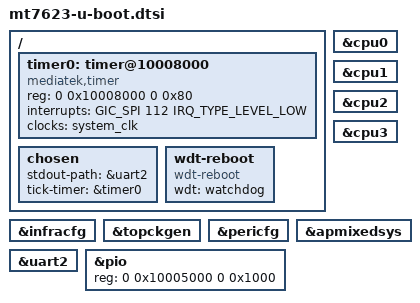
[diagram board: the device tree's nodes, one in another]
// SPDX-License-Identifier: GPL-2.0
/*
 * Copyright (c) 2019 MediaTek Inc.
 * Author: Sam Shih <sam.shih@mediatek.com>
 */

/ {
	timer0: timer@10008000 {
		compatible = "mediatek,timer";
		reg = <0 0x10008000 0 0x80>;
		interrupts = <GIC_SPI 112 IRQ_TYPE_LEVEL_LOW>;
		clocks = <&system_clk>;
		clock-names = "system-clk";
		bootph-all;
	};

	chosen {
		stdout-path = &uart2;
		tick-timer = &timer0;
	};

	wdt-reboot {
		compatible = "wdt-reboot";
		wdt = <&watchdog>;
	};
};

/delete-node/ &bls;
/delete-node/ &larb0;
/delete-node/ &larb1;
/delete-node/ &larb2;
/delete-node/ &iommu;
/delete-node/ &jpegdec;
/delete-node/ &smi_common;
/delete-node/ &ovl;
/delete-node/ &rdma0;
/delete-node/ &rdma1;
/delete-node/ &color;
/delete-node/ &mutex;
/delete-node/ &btif;
/delete-node/ &cec;
/delete-node/ &cir;
/delete-node/ &crypto;
/delete-node/ &dpi0;
/delete-node/ &dsi;
/delete-node/ &mipi_tx0;
/delete-node/ &gmac0;
/delete-node/ &gmac1;
/delete-node/ &eth;
/delete-node/ &hdmi0;
/delete-node/ &hdmiddc0;
/delete-node/ &hdmi_phy;
/delete-node/ &i2c0;
/delete-node/ &i2c1;
/delete-node/ &i2c2;
/delete-node/ &mali;
/delete-node/ &mmc0;
/delete-node/ &mmc1;
/delete-node/ &mt6323keys;
/delete-node/ &mt6323_leds;
/delete-node/ &pcie;
/delete-node/ &pcie0_phy;
/delete-node/ &pcie1_phy;
/delete-node/ &pwm;
/delete-node/ &spi0;
/delete-node/ &spi1;
/delete-node/ &spi2;
/delete-node/ &uart0;
/delete-node/ &uart1;
/delete-node/ &uart3;
/delete-node/ &usb0;
/delete-node/ &usb1;
/delete-node/ &usb2;
/delete-node/ &u2phy1;
/delete-node/ &u3phy1;
/delete-node/ &u3phy2;
/delete-node/ &{/connector};
/delete-node/ &{/wdma@14009000};
/delete-node/ &{/aliases};
/delete-node/ &{/thermal-zones};
/delete-node/ &scpsys;
/delete-node/ &nandc;
/delete-node/ &audsys;
/delete-node/ &hsdma;
/delete-node/ &auxadc;
/delete-node/ &thermal;
/delete-node/ &bch;
/delete-node/ &rng;
/delete-node/ &nor_flash;
/delete-node/ &pwrap;

//delete-node/ &infracfg;
&infracfg {
	bootph-all;
};

//delete-node/ &topckgen;
&topckgen {
	bootph-all;
};

&cpu0{
	/delete-property/ clocks;
	/delete-property/ clock-names;
	/delete-property/ proc-supply;//pwrap
};

&cpu1{
	/delete-property/ clocks;
	/delete-property/ clock-names;
	/delete-property/ proc-supply;//pwrap
};

&cpu2{
	/delete-property/ clocks;
	/delete-property/ clock-names;
	/delete-property/ proc-supply;//pwrap
};

&cpu3{
	/delete-property/ clocks;
	/delete-property/ clock-names;
	/delete-property/ proc-supply;//pwrap
};

&pericfg {
	bootph-all;
};

&apmixedsys {
	bootph-all;
};

&uart2 {
	bootph-all;
	//delete-property/ clocks;
	//delete-property/ clock-names;
};

&pio {
	bootph-all;
	reg = <0 0x10005000 0 0x1000>;
};
